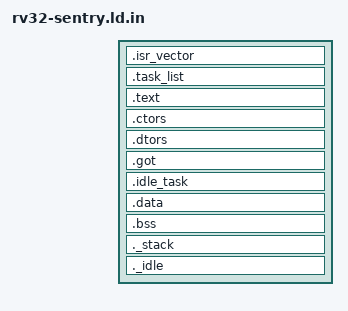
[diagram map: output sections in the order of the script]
/*
 * SPDX-FileCopyrightText: ANSSI
 * SPDX-License-Identifier: Apache-2.0
 */

ENTRY(Reset_Handler)

MEMORY
{
{%- set flash_banks = dts.get_compatible("soc-nv-flash") %}
{%- for flash in flash_banks %}
    {%- set origin = "0x%08x"|format(flash.reg[0]) %}
    {%- set length = "0x%08x"|format(flash.reg[1]) %}
    {{ flash.label.upper() }} (rx): ORIGIN = {{ origin }}, LENGTH = {{ length }}
{%- endfor %}

{%- set sram_banks = dts.get_compatible("mmio-sram") %}
{%- for sram in sram_banks %}
    {%- set origin = "0x%08x"|format(sram.reg[0]) %}
    {%- set length = "0x%08x"|format(sram.reg[1]) %}
    {{ sram.label.upper() }} (rw): ORIGIN = {{ origin }}, LENGTH = {{ length }}
{%- endfor %}

{%- set outpost_pools = dts.get_compatible("outpost,memory-pool") %}
{%- for pool in outpost_pools %}
    {%- set origin = "0x%08x"|format(pool.reg[0]) %}
    {%- set length = "0x%08x"|format(pool.reg[1]) %}
    {{ pool.label.upper() }} (rw): ORIGIN = {{ origin }}, LENGTH = {{ length }}
{%- endfor %}
}

{%- set kernelram_section = dts.chosen["sentry,kernelram_section"].label.upper() %}
{%- set kernelcode_section = dts.chosen["sentry,kernelcode_section"].label.upper() %}
{%- set idleram_section = dts.chosen["sentry,idleram_section"].label.upper() %}
{%- set idlecode_section = dts.chosen["sentry,idlecode_section"].label.upper() %}
{%- set idlecode_size = dts.chosen["sentry,idlecode_section"].reg[1] %}
{%- set idleram_size = dts.chosen["sentry,idleram_section"].reg[1] %}

SECTIONS {
    /* The Reset handler code goes to start of kernelcode section */
    /* Assume that kernel code section in dts starts at reset address */
    .isr_vector :
    {
        _svtor = .;
        KEEP(*(.text.Reset_Handler)) /* Startup code */
        . = ALIGN(4);
    } > {{ kernelcode_section }}

    .task_list (READONLY) :
    {
        . = ALIGN(4);
        KEEP(*(.task_list))
        . = ALIGN(4);
        /*
         * hold all the task static metadata (signed, versioned). Can be upgraded alone.
         * Can be empty at kernel ELF generation (using _task_list pointer in code), but
         * must be fullfill by build system when tasks positioned, based on kernel ELF
         * to be pushed to dedicated memory slot instead, not TEXT
        */
    } > {{ kernelcode_section }}

    /* The program code and other data goes into FLASH */
    .text :
    {
        . = ALIGN(4);
        _stext = .;	            /* create a global symbol at data start */
        *(.text)
        *(.text*)
        *(.rodata)         	/* .rodata sections (constants, strings, etc.) */
        *(.rodata*)         	/* .rodata sections (constants, strings, etc.) */
        /* *(.eh_frame) */   /* Not sure if needed for C and rust on riscv */

        KEEP (*(.init))
        KEEP (*(.fini))

        . = ALIGN(4);
        _etext = .;        	/* define a global symbols at end of code */
        _exit = .;
    } > {{ kernelcode_section }}

    .ctors :
    {
        __CTOR_LIST__ = .;
        /* gcc uses crtbegin.o to find the start of
        the constructors, so we make sure it is
        first.  Because this is a wildcard, it
        doesn't matter if the user does not
        actually link against crtbegin.o; the
        linker won't look for a file to match a
        wildcard.  The wildcard also means that it
        doesn't matter which directory crtbegin.o
        is in.  */
        KEEP (*crtbegin.o(.ctors))
        KEEP (*crtbegin?.o(.ctors))
        /* We don't want to include the .ctor section from
        from the crtend.o file until after the sorted ctors.
        The .ctor section from the crtend file contains the
        end of ctors marker and it must be last */
        KEEP (*(EXCLUDE_FILE(*crtend?.o *crtend.o) .ctors))
        KEEP (*(SORT(.ctors.*)))
        KEEP (*(.ctors))
        __CTOR_END__ = .;
    } > {{ kernelcode_section }}

    .dtors :
    {
        __DTOR_LIST__ = .;
        KEEP (*crtbegin.o(.dtors))
        KEEP (*crtbegin?.o(.dtors))
        KEEP (*(EXCLUDE_FILE(*crtend?.o *crtend.o) .dtors))
        KEEP (*(SORT(.dtors.*)))
        KEEP (*(.dtors))
        __DTOR_END__ = .;
    } > {{ kernelcode_section }}

    /* the .got should be empty. This is checked at the end of this script. */
    .got :
    {
        *(.got .got*)
    } > {{ kernelcode_section }}

    .idle_task :
    {
        . = ALIGN(4);
        _sidle = .;
        _idle = .;
        . = . + {{ idlecode_size }};
        _eidle = .;
        . = ALIGN(4);
    } > {{ idlecode_section }}

    __etext = .;    /* define a global symbol at end of code */
    __DATA_ROM = .; /* Symbol is used by startup for data initialization */

    /* used by the startup to initialize data */
    /* Initialized data sections goes into RAM, load LMA copy after code */
    .data :
    {
        . = ALIGN(4);
        _ram_start = .;
        _sdata = .;        /* create a global symbol at data start */
        *(.data)           /* .data sections */
        *(.data*)          /* .data* sections */
        _edata = .;        /* define a global symbol at data end */
    } > {{ kernelram_section }} AT> {{ kernelcode_section }}

    _sidata = LOADADDR(.data);

    __CACHE_REGION_START = ORIGIN({{ kernelcode_section }});
    __CACHE_REGION_SIZE  = 0;
    __NDATA_ROM = __DATA_ROM + SIZEOF(.data); /* Symbol is used by startup for ncache data initialization */

    /* Uninitialized data section */
    . = ALIGN(4);
    .bss :
    {
        /* This is used by the startup in order to initialize the .bss section */
        _sbss = .;         /* define a global symbol at bss start */
        __bss_start__ = _sbss;
        *debug.o(.bss)
        *(.bss)
        *(.bss*)
        *(COMMON)

        . = ALIGN(4);
        _ebss = .;         /* define a global symbol at bss end */
        __bss_end__ = _ebss;
    } > {{ kernelram_section }}

    /* heap_stack section, used to check that there is enough RAM left */
    ._stack :
    {
        . = ALIGN(4);
        PROVIDE ( end = . );
        PROVIDE ( _end = . );
        . = . + 2048;
        /* top of bootup MSP stack (2k tack) */
        _bootupstack = .;
        _global_pointer = .;
        . = ALIGN(4);
    } > {{ kernelram_section }}

    ._idle :
    {
        _idle_svcexchange = .;
        . = . + {{ idleram_size }};
    } > {{ idleram_section }}
}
